# F28x7x_spi_regs register map
Vendor: Texas Instruments
Peripheral module from a debugger description file (folder C2000).
Address unit: 16 bits
Registers are 16-bit, read-write, no defined reset value unless marked. A register's access mark holds for its fields unless they carry their own. Offsets are as the file gives them; lines under a group give offsets from that group; [hi:lo] are bit positions; {n}, {i} and the like mark numbered series; 'fields as' and 'values as' point back to an identical list; <NAME> marks a mode.

## SPI_REGS — SPI Registers
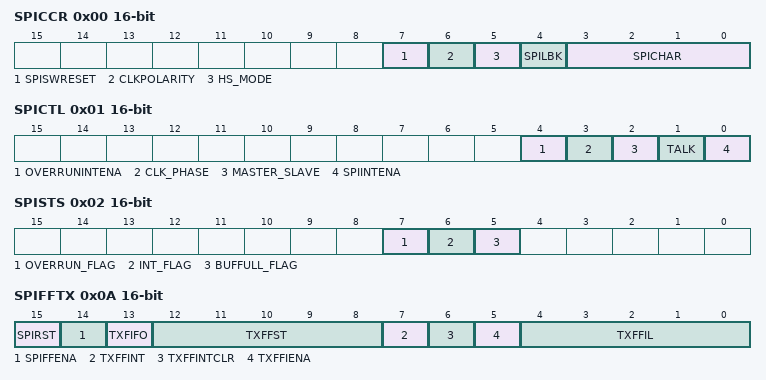
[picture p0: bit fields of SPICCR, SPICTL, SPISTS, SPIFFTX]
0x00 SPICCR — SPI Configuration Control Register
  [7] SPISWRESET — SPI Software Reset
  [6] CLKPOLARITY — Shift Clock Polarity
  [5] HS_MODE — High Speed mode control
  [4] SPILBK — SPI Loopback
  [3:0] SPICHAR — Character Length Control
0x01 SPICTL — SPI Operation Control Register
  [4] OVERRUNINTENA — Overrun Interrupt Enable
  [3] CLK_PHASE — SPI Clock Phase
  [2] MASTER_SLAVE — SPI Network Mode Control
  [1] TALK — Master/Slave Transmit Enable
  [0] SPIINTENA — SPI Interupt Enable
0x02 SPISTS access not given — SPI Status Register
  [7] OVERRUN_FLAG — SPI Receiver Overrun Flag (access W1toClr)
  [6] INT_FLAG — SPI Interrupt Flag (access RtoClr)
  [5] BUFFULL_FLAG ro — SPI Transmit Buffer Full Flag
0x04 SPIBRR — SPI Baud Rate Register
  [6:0] SPI_BIT_RATE — SPI Bit Rate Control
0x06 SPIRXEMU ro — SPI Emulation Buffer Register
  [15:0] ERXBn — Emulation Buffer Received Data
0x07 SPIRXBUF ro — SPI Serial Input Buffer Register
  [15:0] RXBn — Received Data
0x08 SPITXBUF — SPI Serial Output Buffer Register
  [15:0] TXBn — Transmit Data Buffer
0x09 SPIDAT — SPI Serial Data Register
  [15:0] SDATn — Serial Data Shift Register
0x0A SPIFFTX access per field — SPI FIFO Transmit Register
  [15] SPIRST rw — SPI Reset
  [14] SPIFFENA rw — FIFO Enhancements Enable
  [13] TXFIFO rw — TXFIFO Reset
  [12:8] TXFFST ro — Transmit FIFO Status
  [7] TXFFINT ro — TXFIFO Interrupt Flag
  [6] TXFFINTCLR wo — TXFIFO Interrupt Clear
  [5] TXFFIENA rw — TXFIFO Interrupt Enable
  [4:0] TXFFIL rw — TXFIFO Interrupt Level
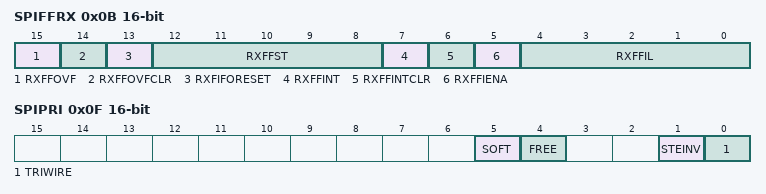
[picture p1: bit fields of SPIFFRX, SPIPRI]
0x0B SPIFFRX access per field — SPI FIFO Receive Register
  [15] RXFFOVF ro — Receive FIFO Overflow Flag
  [14] RXFFOVFCLR wo — Receive FIFO Overflow Clear
  [13] RXFIFORESET rw
  [12:8] RXFFST ro — Receive FIFO Status
  [7] RXFFINT ro — RXFIFO Interrupt Flag
  [6] RXFFINTCLR wo — RXFIFO Interupt Clear
  [5] RXFFIENA rw — RXFIFO Interrupt Enable
  [4:0] RXFFIL rw — RXFIFO Interrupt Level
0x0C SPIFFCT — SPI FIFO Control Register
  [7:0] TXDLY — FIFO Transmit Delay Bits
0x0F SPIPRI — SPI Priority Control Register
  [5] SOFT — Soft emulation mode
  [4] FREE — Free emulation mode
  [1] STEINV — SPISTE inversion bit
  [0] TRIWIRE — 3-wire mode select bit
